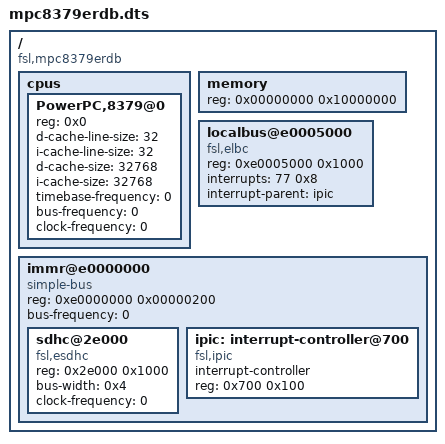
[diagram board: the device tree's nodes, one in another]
// SPDX-License-Identifier: GPL-2.0+ OR X11
/*
 * MPC8379E RDB Device Tree Source
 *
 * Copyright 2020 NXP
 */

/dts-v1/;

/ {
	compatible = "fsl,mpc8379erdb";

	#address-cells = <1>;
	#size-cells = <1>;

	cpus {
		#address-cells = <1>;
		#size-cells = <0>;

		PowerPC,8379@0 {
			device_type = "cpu";
			reg = <0x0>;
			d-cache-line-size = <32>;
			i-cache-line-size = <32>;
			d-cache-size = <32768>;
			i-cache-size = <32768>;
			timebase-frequency = <0>;
			bus-frequency = <0>;
			clock-frequency = <0>;
		};
	};

	memory {
		device_type = "memory";
		reg = <0x00000000 0x10000000>;  // 256MB at 0
	};

	localbus@e0005000 {
		#address-cells = <2>;
		#size-cells = <1>;
		compatible = "fsl,elbc", "simple-bus";
		reg = <0xe0005000 0x1000>;
		interrupts = <77 0x8>;
		interrupt-parent = <&ipic>;
	};

	immr@e0000000 {
		#address-cells = <1>;
		#size-cells = <1>;
		device_type = "soc";
		compatible = "simple-bus";
		ranges = <0 0xe0000000 0x00100000>;
		reg = <0xe0000000 0x00000200>;
		bus-frequency = <0>;

		sdhc@2e000 {
			compatible = "fsl,esdhc";
			reg = <0x2e000 0x1000>;
			bus-width = <0x4>;
			clock-frequency = <0>;
		};

		ipic: interrupt-controller@700 {
			compatible = "fsl,ipic";
			interrupt-controller;
			#address-cells = <0>;
			#interrupt-cells = <2>;
			reg = <0x700 0x100>;
			device_type = "ipic";
		};

	};

};
